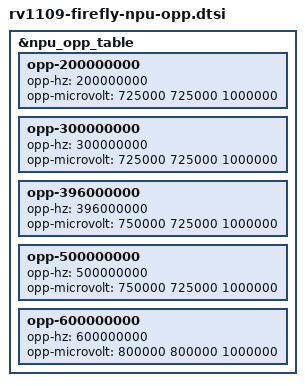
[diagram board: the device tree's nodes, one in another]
&npu_opp_table {
	
	/delete-node/ opp-700000000;
	/delete-node/ opp-800000000;
	/delete-node/ opp-934000000;

       opp-200000000 {
       	opp-hz = /bits/ 64 <200000000>;
       	opp-microvolt = <725000 725000 1000000>;
       };
       opp-300000000 {
       	opp-hz = /bits/ 64 <300000000>;
       	opp-microvolt = <725000 725000 1000000>;
       };
       opp-396000000 {
       	opp-hz = /bits/ 64 <396000000>;
       	opp-microvolt = <750000 725000 1000000>;
       };
       opp-500000000 {
       	opp-hz = /bits/ 64 <500000000>;
       	opp-microvolt = <750000 725000 1000000>;
       };
       opp-600000000 {
       	opp-hz = /bits/ 64 <600000000>;
       	opp-microvolt = <800000 800000 1000000>;
       };
};

